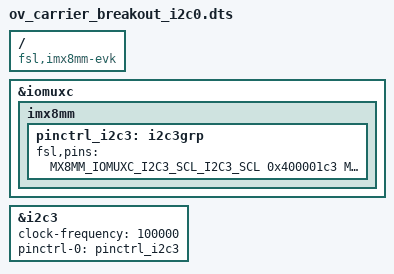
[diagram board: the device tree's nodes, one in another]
/**
 * Portenta-M8 dtb overlay file
 * Arduino 2021
 * Enable I2C0 on Arduino Breakout carrier board
 * Default speed: 100kHz
 */

/dts-v1/;
/plugin/;

#include "imx8mm-pinfunc.h"

/ {
	compatible = "fsl,imx8mm-evk", "fsl,imx8mm";

	fragment@0 {
		target = <&iomuxc>;
		__overlay__ {
			imx8mm {
				pinctrl_i2c3: i2c3grp {
					fsl,pins = <
						MX8MM_IOMUXC_I2C3_SCL_I2C3_SCL      0x400001c3
						MX8MM_IOMUXC_I2C3_SDA_I2C3_SDA      0x400001c3
					>;
				};
			};
		};
	};

	fragment@1 {
		target = <&i2c3>;
		__overlay__ {
			clock-frequency = <100000>;
			pinctrl-names = "default";
			pinctrl-0 = <&pinctrl_i2c3>;
			status = "okay";
		};
	};
};
